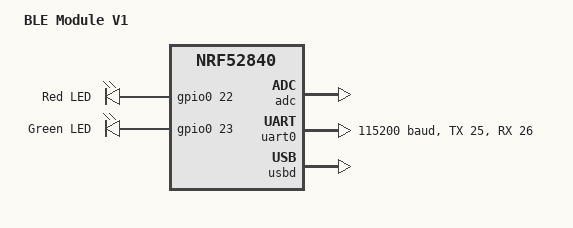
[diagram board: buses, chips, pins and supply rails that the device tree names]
/*
 * Copyright (c) 2021 Joel Svensson
 *
 * SPDX-License-Identifier: Apache-2.0
 */


/*
 * Started with copy of nrf52840_pca10056
*/

/dts-v1/;
#include <nordic/nrf52840_qiaa.dtsi>

/ {
	model = "BLE Module V1";
	compatible = "nordic,nrf52840";

	chosen {
		zephyr,console = &uart0;
		zephyr,shell-uart = &uart0;
		zephyr,uart-mcumgr = &uart0;
		zephyr,bt-mon-uart = &uart0;
		zephyr,bt-c2h-uart = &uart0;
		zephyr,sram = &sram0;
		zephyr,flash = &flash0;
		zephyr,code-partition = &slot0_partition;
	};

	leds {
		compatible = "gpio-leds";
		led0: led_0 {
			gpios = <&gpio0 22 GPIO_ACTIVE_HIGH>;
			label = "Red LED";
		};
		
		led1: led_1 {
			gpios = <&gpio0 23 GPIO_ACTIVE_HIGH>;
			label = "Green LED";
		};
	};

	aliases {
		led0 = &led0;
		led1 = &led1;
	
	};
};

&adc {
	status = "okay";
};

&gpiote {
	status = "okay";
};

&gpio0 {
	status = "okay";
};

&gpio1 {
	status = "okay";
};

/* UART No idea if these settings are correct */
&uart0 {
	compatible = "nordic,nrf-uart";
	status = "okay";
	current-speed = <115200>;
	tx-pin = <25>;
	rx-pin = <26>;
};

&flash0 {
	/*
	 * For more information, see:
	 * http://docs.zephyrproject.org/latest/guides/dts/index.html#flash-partitions
	 */
	partitions {
		compatible = "fixed-partitions";
		#address-cells = <1>;
		#size-cells = <1>;

		boot_partition: partition@0 {
			label = "mcuboot";
			reg = <0x000000000 0x0000C000>;
		};
		slot0_partition: partition@c000 {
			label = "image-0";
			reg = <0x0000C000 0x000067000>;
		};
		slot1_partition: partition@73000 {
			label = "image-1";
			reg = <0x00073000 0x000067000>;
		};
		scratch_partition: partition@da000 {
			label = "image-scratch";
			reg = <0x000da000 0x0001e000>;
		};

		/*
		 * The flash starting at 0x000f8000 and ending at
		 * 0x000fffff is reserved for use by the application.
		 */

		/* Storage partition will be used by FCB/NFFS/NVS if enabled. */
		storage_partition: partition@f8000 {
			label = "storage";
			reg = <0x000f8000 0x00008000>;
		};
	};
};

&usbd {
	compatible = "nordic,nrf-usbd";
	status = "okay";
};
